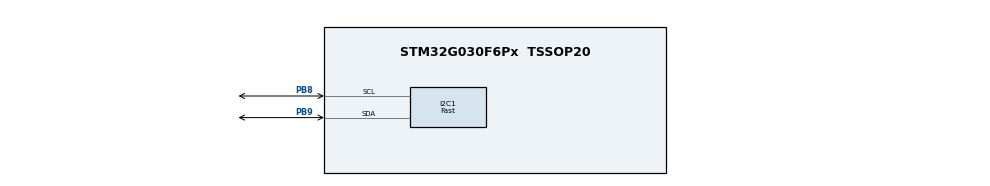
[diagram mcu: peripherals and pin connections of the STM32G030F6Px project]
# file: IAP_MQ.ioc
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CRC.DefaultInitValueUse=DEFAULT_INIT_VALUE_DISABLE
CRC.InitValue=0xffffffff
CRC.InputDataInversionMode=CRC_INPUTDATA_INVERSION_BYTE
CRC.OutputDataInversionMode=CRC_OUTPUTDATA_INVERSION_ENABLE
I2C1.I2C_Speed_Mode=I2C_Fast
I2C1.OwnAddress=0x54<<1
I2C1.Timing=0x0010061A
Mcu.Family=STM32G0
Mcu.Name=STM32G030F6Px
Mcu.Package=TSSOP20
NVIC.I2C1_IRQn=true\:0\:0\:false\:false\:true\:true\:true\:true
PA13.Mode=Serial_Wire
PA13.Signal=SYS_SWDIO
PA14-BOOT0.Mode=Serial_Wire
PA14-BOOT0.Signal=SYS_SWCLK
PA14-BOOT0__PA15.StandardMode=true
PB0__PB1__PB2__PA8.StandardMode=true
PB3__PB4__PB5__PB6.StandardMode=true
PB7__PB8.StandardMode=true
PB8.Mode=I2C
PB8.Signal=I2C1_SCL
PB9.Mode=I2C
PB9.Signal=I2C1_SDA
PC14-OSC32_IN\ (PC14)__PB9.StandardMode=true
ProjectManager.HeapSize=0x200
ProjectManager.StackSize=0x400
ProjectManager.TargetToolchain=STM32CubeIDE
RCC.AHBFreq_Value=16000000
RCC.CortexFreq_Value=16000000
RCC.EXTERNAL_CLOCK_VALUE=12288000
RCC.HCLKFreq_Value=16000000
RCC.HSE_VALUE=8000000
RCC.HSI_VALUE=16000000
RCC.LSE_VALUE=32768
RCC.SYSCLKFreq_VALUE=16000000
RCC.VCOOutputFreq_Value=128000000
VP_CRC_VS_CRC.Mode=CRC_Activate
board=custom

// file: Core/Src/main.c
/* USER CODE BEGIN Header */
/**
 ******************************************************************************
 * @file           : main.c
 * @brief          : Main program body
 ******************************************************************************
 * @attention
 *
 * Copyright (c) 2024 STMicroelectronics.
 * All rights reserved.
 *
 * This software is licensed under terms that can be found in the LICENSE file
 * in the root directory of this software component.
 * If no LICENSE file comes with this software, it is provided AS-IS.
 *
 ******************************************************************************
 */
/* USER CODE END Header */
#include "main.h"

/* USER CODE BEGIN Includes */
#include "stm32g0xx_hal_flash_ex.h"
/* USER CODE END Includes */

/* USER CODE BEGIN PTD */
typedef enum {
    NOEVENT                  = 0,  // not enevt happen
    EVENT_OPCOD_NOTYET_READ  = 1,  // operation code not been read
    EVENT_OPCOD_READ         = 2,  // operation code has been readed
    EVENT_OPCOD_SEND         = 3,  // Feedback the status of MCU
    EVENT_OPCOD_BUSY_RECEIVE = 4   // I2C is in Busy of receive status
    // EVENT_OPCOD_BUSY_SEND =5 //i2C is busy of send
} event_status_t;

typedef void (*pFunction)(void);
/* USER CODE END PTD */

/* USER CODE BEGIN PD */
#define APPLICATION_ADDRESS (0x08001800)
#define FW_LENGTH           (0x6000)
#define FW_CRC_ADDR         ((APPLICATION_ADDRESS) + (FW_LENGTH) - 4)
/* Error codes used to make the red led blinking */
#define ERROR_ERASE              (0x01)
#define ERROR_PROG               (0x02)
#define ERROR_HALF_PROG          (0x04)
#define ERROR_PROG_FLAG          (0x08)
#define ERROR_WRITE_PROTECTION   (0x10)
#define ERROR_FETCH_DURING_ERASE (0x20)
#define ERROR_FETCH_DURING_PROG  (0x40)
#define ERROR_SIZE               (0x80)
#define ERROR_ALIGNMENT          (0x100)
#define ERROR_NOT_ZERO           (0x200)
#define ERROR_UNKNOWN            (0x400)
#define ERROR_I2C                (0x01)
#define ERROR_HSI_TIMEOUT        (0x55)
#define ERROR_PLL_TIMEOUT        (0xAA)
#define ERROR_CLKSWITCH_TIMEOUT  (0xBB)

#define OPC_WREN  (uint8_t)(0x06)
#define OPC_USRCD (uint8_t)(0x77)

#define STM32G0xx_PAGE_SIZE              (0x800)
#define STM32G0xx_FLASH_PAGE0_STARTADDR  (0x8000000)
#define STM32G0xx_FLASH_PAGE1_STARTADDR  (STM32G0xx_FLASH_PAGE0_STARTADDR + STM32G0xx_PAGE_SIZE)
#define STM32G0xx_FLASH_PAGE2_STARTADDR  (STM32G0xx_FLASH_PAGE0_STARTADDR + 2 * STM32G0xx_PAGE_SIZE)
#define STM32G0xx_FLASH_PAGE3_STARTADDR  (STM32G0xx_FLASH_PAGE0_STARTADDR + 3 * STM32G0xx_PAGE_SIZE)
#define STM32G0xx_FLASH_PAGE4_STARTADDR  (STM32G0xx_FLASH_PAGE0_STARTADDR + 4 * STM32G0xx_PAGE_SIZE)
#define STM32G0xx_FLASH_PAGE5_STARTADDR  (STM32G0xx_FLASH_PAGE0_STARTADDR + 5 * STM32G0xx_PAGE_SIZE)
#define STM32G0xx_FLASH_PAGE6_STARTADDR  (STM32G0xx_FLASH_PAGE0_STARTADDR + 6 * STM32G0xx_PAGE_SIZE)
#define STM32G0xx_FLASH_PAGE7_STARTADDR  (STM32G0xx_FLASH_PAGE0_STARTADDR + 7 * STM32G0xx_PAGE_SIZE)
#define STM32G0xx_FLASH_PAGE8_STARTADDR  (STM32G0xx_FLASH_PAGE0_STARTADDR + 8 * STM32G0xx_PAGE_SIZE)
#define STM32G0xx_FLASH_PAGE9_STARTADDR  (STM32G0xx_FLASH_PAGE0_STARTADDR + 9 * STM32G0xx_PAGE_SIZE)
#define STM32G0xx_FLASH_PAGE10_STARTADDR (STM32G0xx_FLASH_PAGE0_STARTADDR + 10 * STM32G0xx_PAGE_SIZE)
#define STM32G0xx_FLASH_PAGE11_STARTADDR (STM32G0xx_FLASH_PAGE0_STARTADDR + 11 * STM32G0xx_PAGE_SIZE)
#define STM32G0xx_FLASH_PAGE12_STARTADDR (STM32G0xx_FLASH_PAGE0_STARTADDR + 12 * STM32G0xx_PAGE_SIZE)
#define STM32G0xx_FLASH_PAGE13_STARTADDR (STM32G0xx_FLASH_PAGE0_STARTADDR + 13 * STM32G0xx_PAGE_SIZE)
#define STM32G0xx_FLASH_PAGE14_STARTADDR (STM32G0xx_FLASH_PAGE0_STARTADDR + 14 * STM32G0xx_PAGE_SIZE)
#define STM32G0xx_FLASH_PAGE15_STARTADDR (STM32G0xx_FLASH_PAGE0_STARTADDR + 15 * STM32G0xx_PAGE_SIZE)

// #define FLASH_PAGE_SIZE         ((uint32_t)0x00000800)   /* FLASH Page Size */
#define FLASH_USER_START_ADDR STM32G0xx_FLASH_PAGE5_STARTADDR /* Start @ of user Flash area */
#define FLASH_USER_END_ADDR   STM32G0xx_FLASH_PAGE6_STARTADDR /* End @ of user Flash area */
#define DATA_32               ((uint32_t)0x22446688)
/* USER CODE END PD */

CRC_HandleTypeDef hcrc;

/* USER CODE BEGIN PV */
volatile uint16_t I2C_Receive_Counter = 0;
volatile uint8_t Receive_Buffer[2056];
volatile event_status_t i2c_event = NOEVENT;
volatile uint16_t error;
volatile uint32_t NbrOfPage    = 0x00;
volatile uint32_t EraseCounter = 0x00, Address = 0x00;
volatile uint32_t JumpAddress;
volatile pFunction JumpToApplication;
volatile uint8_t opcode;
/* USER CODE END PV */

void SystemClock_Config(void);
static void MX_GPIO_Init(void);
static void MX_I2C1_Init(void);
static void MX_CRC_Init(void);

/* USER CODE BEGIN 0 */
uint8_t compute_fw_crc32(void)
{
    uint32_t crcsum, crc_read, len;
    uint8_t *pdata = (uint8_t *)APPLICATION_ADDRESS;
    len            = FW_LENGTH - 4;
    crc_read       = *(uint32_t *)FW_CRC_ADDR;
    crcsum         = HAL_CRC_Calculate(&hcrc, (uint32_t *)pdata, len) ^ 0xffffffff;
    if (crc_read == crcsum)
        return 1;
    else
        return 0;
}

/**
 * @brief  Gets the page of a given address
 * @param  Addr: Address of the FLASH Memory
 * @retval The page of a given address
 */
static uint32_t get_page(uint32_t Addr)
{
    return (Addr - STM32G0xx_FLASH_PAGE0_STARTADDR) / FLASH_PAGE_SIZE;
    ;
}

/**
 * Brief   This function handles I2C1 interrupt request.
 * Param   None
 * Retval  I2C1 always as slave of i2c conmunication
 */
void I2C1_IRQHandler(void)
{
    uint32_t I2C_InterruptStatus = I2C1->ISR; /* Get interrupt status */

    if ((I2C_InterruptStatus & I2C_ISR_ADDR) == I2C_ISR_ADDR) /* Check address match */
    {
        I2C1->ICR |= I2C_ICR_ADDRCF; /* Clear address match flag*/

        if ((I2C1->ISR & I2C_ISR_DIR) == I2C_ISR_DIR) /* Check if transfer direction is read (slave transmitter) */
        {
            I2C1->CR1 |= I2C_CR1_TXIE;    /* Set transmit IT /status*/
            i2c_event = EVENT_OPCOD_SEND; /* Set I2C  entor transmit mode*/

        } else /*Write operation, slave receive status*/
        {
            I2C1->CR1 |= I2C_CR1_RXIE;            /* Set receive IT /status*/
            i2c_event = EVENT_OPCOD_BUSY_RECEIVE; /* Set I2C  entor receive mode*/
        }

        I2C1->CR1 |= I2C_CR1_STOPIE;  // Enable STOP interrupt

    } else if ((I2C_InterruptStatus & I2C_ISR_TXIS) == I2C_ISR_TXIS) {
        // add some application code in this place
    }
    /*check RXDR is not empty*/
    else if ((I2C_InterruptStatus & I2C_ISR_RXNE) == I2C_ISR_RXNE) {
        // I2C_ISR_RXNE add you code in this place Tomas Li add
        Receive_Buffer[I2C_Receive_Counter++] = I2C1->RXDR;
        i2c_event                             = EVENT_OPCOD_BUSY_RECEIVE;  // slave is busy for receive data

    } else if ((I2C_InterruptStatus & I2C_ISR_NACKF) == I2C_ISR_NACKF) {
    }
    /*check Stop event happen */
    if ((I2C_InterruptStatus & I2C_ISR_STOPF) == I2C_ISR_STOPF) {
        I2C1->ICR |= I2C_ICR_STOPCF;  // clear the STOP interrupt Flag

#if 1
        switch (i2c_event) {
            case EVENT_OPCOD_BUSY_RECEIVE:  // slave receive status Stop flag
                I2C_Receive_Counter = 0;
                i2c_event           = EVENT_OPCOD_NOTYET_READ;

                I2C1->CR1 &= ~(I2C_CR1_STOPIE);  // Disable all interrupt.except Error interrupt
                I2C1->CR2 |= I2C_CR2_NACK;       // set feedback Nack in next event
                I2C1->CR1 |= I2C_CR1_ADDRIE;
                break;
            case EVENT_OPCOD_SEND:                                              // slave send stop
                I2C1->ICR |= I2C_ICR_STOPCF | I2C_ICR_NACKCF | I2C_ICR_BERRCF;  // clear the STOP interrupt Flag
                I2C1->CR1 |= I2C_CR1_ADDRIE;
                i2c_event = NOEVENT;

                break;
            default:

                break;
        }
#endif

    } else {
        error = ERROR_I2C; /* Report an error */
    }
}

void reset_all_periph(void)
{
    LL_I2C_DeInit(I2C2);
    LL_I2C_DisableAutoEndMode(I2C2);
    LL_I2C_Disable(I2C2);
    LL_I2C_DisableIT_ADDR(I2C2);
    SysTick->CTRL = 0;
    SYSCFG->CFGR1 &= SYSCFG_CFGR1_MEM_MODE;
    NVIC->ICER[0] = 0xFFFFFFFF;
    NVIC->ICPR[0] = 0xFFFFFFFF;
    /* Set EXTICRx registers to reset value */
    EXTI->EXTICR[0] = 0;
    EXTI->EXTICR[1] = 0;
    EXTI->EXTICR[2] = 0;
    EXTI->EXTICR[3] = 0;
    /* Set CFGR2 register to reset value: clear SRAM parity error flag */
    SYSCFG->CFGR2 |= (uint32_t)SYSCFG_CFGR2_SRAM_PE;
    LL_RCC_DeInit();
    HAL_CRC_DeInit(&hcrc);
    HAL_DeInit();
    SysTick->CTRL = 0;
    SysTick->LOAD = 0;
    SysTick->VAL  = 0;
}

void jump_app(void)
{
    if (compute_fw_crc32()) {
        /*check the application address context whether avilible*/
        if (((*(__IO uint32_t *)APPLICATION_ADDRESS) & 0x2FFE0000) == 0x20000000) {
            reset_all_periph();
            SCB->VTOR = APPLICATION_ADDRESS;
            /* Jump to user application */
            JumpAddress       = *(__IO uint32_t *)(APPLICATION_ADDRESS + 4);
            JumpToApplication = (pFunction)JumpAddress;
            /* Initialize user application's Stack Pointer */
            __set_MSP(*(__IO uint32_t *)APPLICATION_ADDRESS);
            JumpToApplication();
        }
    }
}

void write_code(void)
{
    uint16_t Number_Bytes_Transferred = 0;
    uint32_t Add_Flash, end_add_flash;
    uint64_t Data       = 0;
    uint16_t Data_index = 8;
    uint32_t PageError  = 0;
    FLASH_EraseInitTypeDef My_Flash;
    uint32_t PageNum = 0;

    Add_Flash     = Receive_Buffer[1] << 24 | Receive_Buffer[2] << 16 | Receive_Buffer[3] << 8 | Receive_Buffer[4] << 0;
    end_add_flash = Add_Flash + 2048;

    if (Add_Flash < APPLICATION_ADDRESS) {
        return;
    }

    Number_Bytes_Transferred = (Receive_Buffer[5] << 8) + Receive_Buffer[6];

    if (Number_Bytes_Transferred > 0) {
        if (__HAL_FLASH_GET_FLAG(FLASH_FLAG_CFGBSY) != 0x00U) {
            *(uint32_t *)(Add_Flash + 600) = 12323;
            FLASH->SR                      = FLASH_SR_CLEAR;
        }
    step_unlock:
        if (HAL_FLASH_Unlock() != HAL_OK) {
            goto step_unlock;
        }

        PageNum = get_page(Add_Flash);

        My_Flash.TypeErase = FLASH_TYPEERASE_PAGES;
        My_Flash.Page      = PageNum;
        My_Flash.NbPages   = 1;

    step_erase:
        FLASH_WaitForLastOperation(50);
        if (HAL_FLASHEx_Erase(&My_Flash, &PageError) != HAL_OK) {
            goto step_erase;
        }  // 调用擦除函数擦除

        while (Add_Flash < end_add_flash) {
            Data = Receive_Buffer[Data_index] | ((uint64_t)Receive_Buffer[Data_index + 1] << 8) |
                   ((uint64_t)Receive_Buffer[Data_index + 2] << 16) | ((uint64_t)Receive_Buffer[Data_index + 3] << 24) |
                   ((uint64_t)Receive_Buffer[Data_index + 4] << 32) | ((uint64_t)Receive_Buffer[Data_index + 5] << 40) |
                   ((uint64_t)Receive_Buffer[Data_index + 6] << 48) | ((uint64_t)Receive_Buffer[Data_index + 7] << 56);

        step_write:
            FLASH_WaitForLastOperation(50);
            if (HAL_FLASH_Program(FLASH_TYPEPROGRAM_DOUBLEWORD, Add_Flash, Data) != HAL_OK) {
                goto step_write;
            }
            Add_Flash  = Add_Flash + 8;
            Data_index = Data_index + 8;
        }
        HAL_FLASH_Lock();
        FLASH_WaitForLastOperation(50);
    }
    for (int i = 0; i < sizeof(Receive_Buffer); i++) {
        Receive_Buffer[i] = 0;
    }
}

void iap_i2c(void)
{
    /*this is a endless loop for process the data from Host side*/
    while (1) {
        if (i2c_event == EVENT_OPCOD_NOTYET_READ) {
            NVIC_DisableIRQ(I2C2_IRQn);
            i2c_event = NOEVENT;  // changed the status
            /* Read opcode */
            switch (Receive_Buffer[0]) {
                case OPC_WREN:
                    write_code();
                    break;
                case OPC_USRCD:
                    jump_app();
                    break;
                default:
                    break;
            }
            NVIC_EnableIRQ(I2C2_IRQn);
            I2C2->CR1 |= I2C_CR1_ADDRIE;  // Open address and Stop interrupt
            LL_I2C_Enable(I2C2);
            LL_I2C_EnableIT_ADDR(I2C2);
        }
    }
}

static void iap_gpio_init(void)
{
    GPIO_InitTypeDef GPIO_InitStruct = {0};

    /* GPIO Ports Clock Enable */
    __HAL_RCC_GPIOB_CLK_ENABLE();

    /* Configure GPIO pin Output Level */
    HAL_GPIO_WritePin(GPIOB, GPIO_PIN_8 | GPIO_PIN_9, GPIO_PIN_RESET);

    /* Configure GPIO pin : PB7 */
    GPIO_InitStruct.Pin   = GPIO_PIN_8 | GPIO_PIN_9;
    GPIO_InitStruct.Mode  = GPIO_MODE_INPUT;
    GPIO_InitStruct.Pull  = GPIO_PULLUP;
    GPIO_InitStruct.Speed = GPIO_SPEED_FREQ_LOW;
    HAL_GPIO_Init(GPIOB, &GPIO_InitStruct);
}
/* USER CODE END 0 */

int main(void)
{

    /* MCU Configuration--------------------------------------------------------*/

    /* Reset of all peripherals, Initializes the Flash interface and the Systick. */
    HAL_Init();

    /* Configure the system clock */
    SystemClock_Config();

    /* Initialize all configured peripherals */
    MX_GPIO_Init();
    //	MX_I2C1_Init();
    MX_CRC_Init();
    /* USER CODE BEGIN 2 */
    iap_gpio_init();
    LL_mDelay(300);
    if ((!(!!(GPIOB->IDR & GPIO_PIN_8))) && (!(!!(GPIOB->IDR & GPIO_PIN_9)))) {
        MX_I2C1_Init();
        LL_I2C_Enable(I2C1);
        LL_I2C_EnableIT_ADDR(I2C1);
        iap_i2c();
    } else {
        jump_app();
    }
    MX_I2C1_Init();
    LL_I2C_Enable(I2C1);
    LL_I2C_EnableIT_ADDR(I2C1);
    iap_i2c();
    /* USER CODE END 2 */

    /* Infinite loop */
    while (1) {

    }
}

void SystemClock_Config(void)
{
    /* HSI configuration and activation */
    LL_RCC_HSI_Enable();
    while (LL_RCC_HSI_IsReady() != 1) {
    }

    /* Set AHB prescaler*/
    LL_RCC_SetAHBPrescaler(LL_RCC_SYSCLK_DIV_1);

    /* Sysclk activation on the HSI */
    LL_RCC_SetSysClkSource(LL_RCC_SYS_CLKSOURCE_HSI);
    while (LL_RCC_GetSysClkSource() != LL_RCC_SYS_CLKSOURCE_STATUS_HSI) {
    }

    /* Set APB1 prescaler*/
    LL_RCC_SetAPB1Prescaler(LL_RCC_APB1_DIV_1);
    /* Update CMSIS variable (which can be updated also through SystemCoreClockUpdate function) */
    LL_SetSystemCoreClock(16000000);

    /* Update the time base */
    if (HAL_InitTick(TICK_INT_PRIORITY) != HAL_OK) {
        Error_Handler();
    }
}

static void MX_CRC_Init(void)
{

    hcrc.Instance                     = CRC;
    hcrc.Init.DefaultPolynomialUse    = DEFAULT_POLYNOMIAL_ENABLE;
    hcrc.Init.DefaultInitValueUse     = DEFAULT_INIT_VALUE_DISABLE;
    hcrc.Init.InitValue               = 0xffffffff;
    hcrc.Init.InputDataInversionMode  = CRC_INPUTDATA_INVERSION_BYTE;
    hcrc.Init.OutputDataInversionMode = CRC_OUTPUTDATA_INVERSION_ENABLE;
    hcrc.InputDataFormat              = CRC_INPUTDATA_FORMAT_BYTES;
    if (HAL_CRC_Init(&hcrc) != HAL_OK) {
        Error_Handler();
    }
}

static void MX_I2C1_Init(void)
{

    LL_I2C_InitTypeDef I2C_InitStruct = {0};

    LL_GPIO_InitTypeDef GPIO_InitStruct = {0};

    LL_RCC_SetI2CClockSource(LL_RCC_I2C1_CLKSOURCE_PCLK1);

    LL_IOP_GRP1_EnableClock(LL_IOP_GRP1_PERIPH_GPIOB);
    /**I2C1 GPIO Configuration
     PB8   ------> I2C1_SCL
     PB9   ------> I2C1_SDA
     */
    GPIO_InitStruct.Pin        = LL_GPIO_PIN_8;
    GPIO_InitStruct.Mode       = LL_GPIO_MODE_ALTERNATE;
    GPIO_InitStruct.Speed      = LL_GPIO_SPEED_FREQ_LOW;
    GPIO_InitStruct.OutputType = LL_GPIO_OUTPUT_OPENDRAIN;
    GPIO_InitStruct.Pull       = LL_GPIO_PULL_NO;
    GPIO_InitStruct.Alternate  = LL_GPIO_AF_6;
    LL_GPIO_Init(GPIOB, &GPIO_InitStruct);

    GPIO_InitStruct.Pin        = LL_GPIO_PIN_9;
    GPIO_InitStruct.Mode       = LL_GPIO_MODE_ALTERNATE;
    GPIO_InitStruct.Speed      = LL_GPIO_SPEED_FREQ_LOW;
    GPIO_InitStruct.OutputType = LL_GPIO_OUTPUT_OPENDRAIN;
    GPIO_InitStruct.Pull       = LL_GPIO_PULL_NO;
    GPIO_InitStruct.Alternate  = LL_GPIO_AF_6;
    LL_GPIO_Init(GPIOB, &GPIO_InitStruct);

    /* Peripheral clock enable */
    LL_APB1_GRP1_EnableClock(LL_APB1_GRP1_PERIPH_I2C1);

    /* I2C1 interrupt Init */
    NVIC_SetPriority(I2C1_IRQn, 0);
    NVIC_EnableIRQ(I2C1_IRQn);

    /** I2C Initialization
     */
    I2C_InitStruct.PeripheralMode  = LL_I2C_MODE_I2C;
    I2C_InitStruct.Timing          = 0x0010061A;
    I2C_InitStruct.AnalogFilter    = LL_I2C_ANALOGFILTER_ENABLE;
    I2C_InitStruct.DigitalFilter   = 0;
    I2C_InitStruct.OwnAddress1     = 0x54 << 1;
    I2C_InitStruct.TypeAcknowledge = LL_I2C_ACK;
    I2C_InitStruct.OwnAddrSize     = LL_I2C_OWNADDRESS1_7BIT;
    LL_I2C_Init(I2C1, &I2C_InitStruct);
    LL_I2C_EnableAutoEndMode(I2C1);
    LL_I2C_SetOwnAddress2(I2C1, 0, LL_I2C_OWNADDRESS2_NOMASK);
    LL_I2C_DisableOwnAddress2(I2C1);
    LL_I2C_DisableGeneralCall(I2C1);
    LL_I2C_EnableClockStretching(I2C1);
}

static void MX_GPIO_Init(void)
{
    /* GPIO Ports Clock Enable */
    __HAL_RCC_GPIOB_CLK_ENABLE();
    __HAL_RCC_GPIOA_CLK_ENABLE();
}

void Error_Handler(void)
{
    __disable_irq();
    while (1) {
    }
}
